# ulp_phy_model: IP-XACT component
VLNV IcronTechnologies:IcronTechnologies:ulp_phy_model:1.0

## Parameters
addr_width = 8
bus_width = 32

## Bus interfaces (logical=physical port)
default_map: slave AGNISYS:AGNISYS:APB:1.0, memory map ulp_phymap
  pclk=pclk, presetn=presetn, psel=psel, penable=penable, pwrite=pwrite, pprot=pprot, pstrb=pstrb, pwdata=pwdata, paddr=paddr, pready=pready, prdata=prdata, pslverr=pslverr

## Ports
in pclk
in presetn
in psel
in penable
in pwrite
in pprot[2:0]
in pstrb[(bus_width div 8 )-1:0]
in pwdata[bus_width -1:0]
in paddr[addr_width -1:0]
out pready
out prdata[bus_width -1:0]
out pslverr
out ulp_phy_regsversion_major_r[7:0]
out ulp_phy_regsversion_minor_r[7:0]
out ulp_phy_regsversion_patch_r[7:0]
out ulp_phy_regspipe_ctrl_enb
out ulp_phy_regspipe_ctrl_tx_swing_r
out ulp_phy_regspipe_ctrl_tx_margin_r[2:0]
out ulp_phy_regspipe_ctrl_tx_deemph_r[1:0]
out ulp_phy_regspipe_ctrl_reset_n_r
out ulp_phy_regspipe_ctrl_rx_eq_training_r
out ulp_phy_regspipe_ctrl_elas_buf_mode_r
out ulp_phy_regscompliancy_ctrl_enb
out ulp_phy_regscompliancy_ctrl_gen_lfps_ping_r
in ulp_phy_regscompliancy_ctrl_gen_lfps_ping_hw_clear
out ulp_phy_regsstats0_rd2clr_config_rd_valid_out
out ulp_phy_regsstats0_rd2clr_config_wr_valid_out
out ulp_phy_regsstats0_rx_8b10b_err_rd_valid_out
out ulp_phy_regsstats0_rx_elastic_buff_overflow_rd_valid_out
out ulp_phy_regsstats0_rx_elastic_buff_underflow_rd_valid_out
out ulp_phy_regsstats0_rx_disparity_err_rd_valid_out
out ulp_phy_regsstats1_rd2clr_config_rd_valid_out
out ulp_phy_regsstats1_rd2clr_config_wr_valid_out
out ulp_phy_regsstats1_skp_insert_in_err_rd_valid_out
out ulp_phy_regsstats1_crc5_chk_failed_rd_valid_out
out ulp_phy_regsstats1_crc16_chk_failed_rd_valid_out
out ulp_phy_regsstats1_dpp_abort_rd_valid_out
out ulp_phy_regsstats1_rx_framer_ptp_violated_rd_valid_out

## Address spaces and blocks
ulp_phymap.ulp_phy: base 0x000, range 0x100, width 32

## Registers
Registers are 32-bit, read-only, reset 0x0 unless marked. A register's access mark holds for its fields unless they carry their own. Offsets are from the block's base; lines under a group give offsets from that group; [hi:lo] are bit positions; {n}, {i} and the like mark numbered series; 'fields as' and 'values as' point back to an identical list; <NAME> marks a mode.

## ulp_phymap.ulp_phy — All Registers in the PHY clock domain (250MHz)
Base 0x00000000
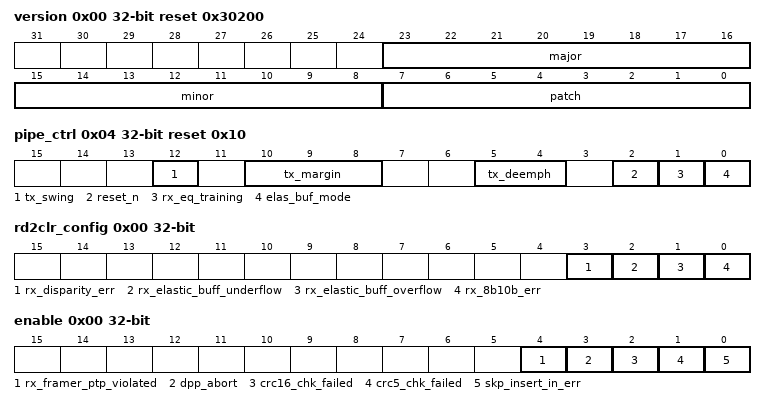
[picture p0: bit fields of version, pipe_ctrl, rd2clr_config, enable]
0x00 version reset 0x30200 — 3.1.0: Changed the Interrupt Pending to avoid blocking the register update when enable is 0 3.2.0: Added pending_irq register
  [23:16] major — Major version
  [15:8] minor — Minor version
  [7:0] patch — Patch version
0x04 pipe_ctrl rw reset 0x10
  [12] tx_swing — TX Voltage Swing Level (0=Full, 1=Low) -See PIPE Spec V3.0 Table 5-3
  [10:8] tx_margin — TX Voltage Level (0=Normal Operating Range) -See PIPE Spec V3.0 Table 5-3
  [5:4] tx_deemph — TX De-emphasis (0=-6dB, 1=-3.5dB, 2=No De-Emphasis, 3=Reserved -See PIPE Spec V3.0 Table 5-3
  [2] reset_n — Resets the TX and RX (***NOTE USED NOW. PLACE HOLDER FOR LATER) -See PIPE Spec V3.0 Table 5-3
  [1] rx_eq_training — Instructs the RX to bypass normal operation to perform equalization training -See PIPE Spec V3.0 Table 5-3
  [0] elas_buf_mode — Elasticity Buffer Mode (Nominal Half Full when 0 and Nominal Empty when 1) -See PIPE Spec V3.0 Table 5-3
0x08 compliancy_ctrl rw — Provides manual access to do the compliancy testing if needed and the right hardware is not available
  [0] gen_lfps_ping — When set, it signals an LFPS ping has been received in the compliancy logic forcing the next compliancy pattern Write a 1 and HW clears it when completed the action
0x0C stats0 group — All the Statistic Registers and their configuration for the ULP PHY Stats
  0x00 rd2clr_config rw — Configures if the stats register read by s/w clears the read register. A 1 in any bit configures the h/w to clear the corresponding stats register after a s/w read of that stats register.
    [3] rx_disparity_err, [2] rx_elastic_buff_underflow, [1] rx_elastic_buff_overflow, [0] rx_8b10b_err
  0x04 rx_8b10b_err — Count of the 8B/10B decoder error in the PHY RX. This is based on the encoding of RxStatus[2:0] in the PIPE Standard
    [15:0] rx_8b10b_err
  0x08 rx_elastic_buff_overflow — Count of the Elastic Buffer Overflows in the PHY RX. This is based on the encoding of RxStatus[2:0] in the PIPE Standard
    [15:0] rx_elastic_buff_overflow
  0x0C rx_elastic_buff_underflow — Count of the Elastic Buffer Underflows in the PHY RX. This is based on the encoding of RxStatus[2:0] in the PIPE Standard
    [15:0] rx_elastic_buff_underflow
  0x10 rx_disparity_err — Count of the Disparity error in the PHY RX. This is based on the encoding of RxStatus[2:0] in the PIPE Standard
    [15:0] rx_disparity_err
0x20 stats1 group — All the Statistic Registers and their configuration for the ULP logic
  0x00 rd2clr_config rw — Configures if the stats register read by s/w clears the read register. A 1 in any bit configures the h/w to clear the corresponding stats register after a s/w read of that stats register.
    [4] rx_framer_ptp_violated, [3] dpp_abort, [2] crc16_chk_failed, [1] crc5_chk_failed, [0] skp_insert_in_err
  0x04 skp_insert_in_err — Count the number of the erroneous skip injection
    [15:0] skp_insert_in_err
  0x08 crc5_chk_failed — Count the number of detected crc5 errors
    [7:0] crc5_chk_failed
  0x0C crc16_chk_failed — Count the number of detected crc16 errors
    [7:0] crc16_chk_failed
  0x10 dpp_abort — Count the number of DPP abort symbols received in a Transaction Packet
    [7:0] dpp_abort
  0x14 rx_framer_ptp_violated — Count the number of PTP Protocol Violation in the RX Frame Manager
    [7:0] rx_framer_ptp_violated
0x38 irq0 group — Define the IRQ group
  0x00 enable rw — These are enable for the actual interrupt signals
    [4] rx_framer_ptp_violated — Fires on PTP Protocol Violation in the RX Frame Manager
    [3] dpp_abort — Fires on DPP abort symbols received in a Transaction Packet
    [2] crc16_chk_failed — Fires on detected crc16 errors
    [1] crc5_chk_failed — Fires on detected crc5 errors
    [0] skp_insert_in_err — Fires on erroneous skip injection
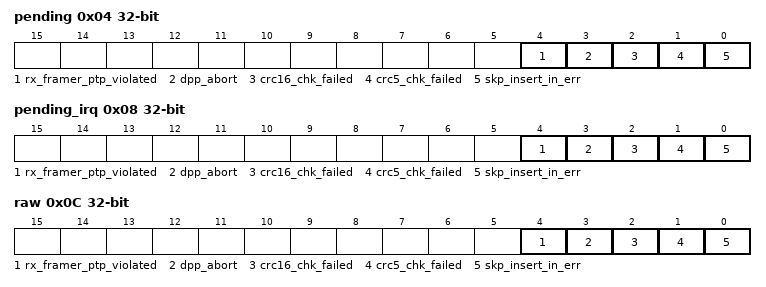
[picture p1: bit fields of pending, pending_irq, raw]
  0x04 pending rw — The actual interrupt singal
    [4] rx_framer_ptp_violated write-1-clears — Fires on PTP Protocol Violation in the RX Frame Manager
    [3] dpp_abort write-1-clears — Fires on DPP abort symbols received in a Transaction Packet
    [2] crc16_chk_failed write-1-clears — Fires on detected crc16 errors
    [1] crc5_chk_failed write-1-clears — Fires on detected crc5 errors
    [0] skp_insert_in_err write-1-clears — Fires on erroneous skip injection
  0x08 pending_irq — Registered version of pending & enable
    fields as irq0.enable
  0x0C raw — The Raw value for the interrupt signals
    fields as irq0.enable
